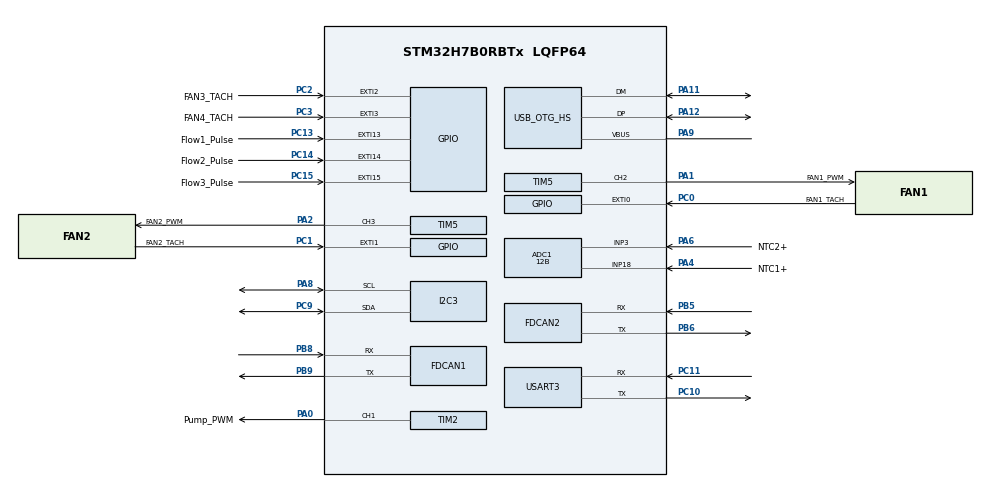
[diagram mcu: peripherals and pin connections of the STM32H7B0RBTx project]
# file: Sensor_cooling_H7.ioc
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ADC1.Channel-0\#ChannelRegularConversion=ADC_CHANNEL_3
ADC1.Channel-1\#ChannelRegularConversion=ADC_CHANNEL_18
ADC1.ClockPrescaler=ADC_CLOCK_ASYNC_DIV64
ADC1.ConversionDataManagement=ADC_CONVERSIONDATA_DMA_CIRCULAR
ADC1.ExternalTrigConv=ADC_EXTERNALTRIG_T6_TRGO
ADC1.NbrOfConversion=2
ADC1.NbrOfConversionFlag=1
ADC1.OffsetNumber-0\#ChannelRegularConversion=ADC_OFFSET_NONE
ADC1.OffsetNumber-1\#ChannelRegularConversion=ADC_OFFSET_NONE
ADC1.OffsetSignedSaturation-0\#ChannelRegularConversion=DISABLE
ADC1.OffsetSignedSaturation-1\#ChannelRegularConversion=DISABLE
ADC1.Rank-0\#ChannelRegularConversion=1
ADC1.Rank-1\#ChannelRegularConversion=2
ADC1.Resolution=ADC_RESOLUTION_12B
ADC1.SamplingTime-0\#ChannelRegularConversion=ADC_SAMPLETIME_810CYCLES_5
ADC1.SamplingTime-1\#ChannelRegularConversion=ADC_SAMPLETIME_810CYCLES_5
ADC1.master=1
Dma.ADC1.0.Direction=DMA_PERIPH_TO_MEMORY
Dma.ADC1.0.EventEnable=DISABLE
Dma.ADC1.0.FIFOMode=DMA_FIFOMODE_DISABLE
Dma.ADC1.0.Instance=DMA1_Stream0
Dma.ADC1.0.MemDataAlignment=DMA_MDATAALIGN_HALFWORD
Dma.ADC1.0.MemInc=DMA_MINC_ENABLE
Dma.ADC1.0.Mode=DMA_CIRCULAR
Dma.ADC1.0.PeriphDataAlignment=DMA_PDATAALIGN_HALFWORD
Dma.ADC1.0.PeriphInc=DMA_PINC_DISABLE
Dma.ADC1.0.Polarity=HAL_DMAMUX_REQ_GEN_RISING
Dma.ADC1.0.Priority=DMA_PRIORITY_LOW
Dma.ADC1.0.RequestNumber=1
Dma.ADC1.0.SignalID=NONE
Dma.ADC1.0.SyncEnable=DISABLE
Dma.ADC1.0.SyncPolarity=HAL_DMAMUX_SYNC_NO_EVENT
Dma.ADC1.0.SyncRequestNumber=1
Dma.ADC1.0.SyncSignalID=NONE
Dma.Request0=ADC1
FDCAN1.CalculateBaudRateNominal=500000
FDCAN1.CalculateTimeBitNominal=2000
FDCAN1.CalculateTimeQuantumNominal=142.85714285714286
FDCAN1.NominalPrescaler=20
FDCAN1.NominalTimeSeg1=11
FDCAN1.NominalTimeSeg2=2
FDCAN1.RxFifo0ElmtsNbr=32
FDCAN1.StdFiltersNbr=1
FDCAN1.TxFifoQueueElmtsNbr=32
FDCAN2.CalculateBaudRateNominal=2916666
FDCAN2.CalculateTimeBitNominal=342
FDCAN2.CalculateTimeQuantumNominal=114.28571428571429
I2C3.Analog_Filter=I2C_ANALOGFILTER_DISABLE
I2C3.OwnAddress=0x50
I2C3.Timing=0x30808BD0
Mcu.Family=STM32H7
Mcu.Name=STM32H7B0RBTx
Mcu.Package=LQFP64
NVIC.ADC_IRQn=true\:0\:0\:false\:false\:true\:true\:true\:true
NVIC.DMA1_Stream0_IRQn=true\:0\:0\:false\:false\:true\:false\:true\:true
NVIC.FDCAN1_IT0_IRQn=true\:0\:0\:false\:false\:true\:true\:true\:true
NVIC.FDCAN1_IT1_IRQn=true\:0\:0\:false\:false\:true\:true\:true\:true
NVIC.PriorityGroup=NVIC_PRIORITYGROUP_4
PA0.GPIO_Label=Pump_PWM
PA0.Signal=S_TIM2_CH1_ETR
PA1.GPIO_Label=FAN1_PWM
PA1.Signal=S_TIM5_CH2
PA11.Mode=Device_Only_FS
PA11.Signal=USB_OTG_HS_DM
PA12.Mode=Device_Only_FS
PA12.Signal=USB_OTG_HS_DP
PA13.Mode=Trace_Asynchronous_SW
PA13.Signal=DEBUG_JTMS-SWDIO
PA14.Mode=Trace_Asynchronous_SW
PA14.Signal=DEBUG_JTCK-SWCLK
PA2.GPIO_Label=FAN2_PWM
PA2.Signal=S_TIM5_CH3
PA4.GPIO_Label=NTC1+
PA4.Signal=ADCx_INP18
PA6.GPIO_Label=NTC2+
PA6.Signal=ADCx_INP3
PA8.Mode=I2C
PA8.Signal=I2C3_SCL
PA9.Mode=Activate_VBUS_FS
PA9.Signal=USB_OTG_HS_VBUS
PB3.Mode=Trace_Asynchronous_SW
PB3.Signal=DEBUG_JTDO-SWO
PB5.Mode=FDCAN_Activate
PB5.Signal=FDCAN2_RX
PB6.Mode=FDCAN_Activate
PB6.Signal=FDCAN2_TX
PB8.Mode=FDCAN_Activate
PB8.Signal=FDCAN1_RX
PB9.Mode=FDCAN_Activate
PB9.Signal=FDCAN1_TX
PC0.GPIO_Label=FAN1_TACH
PC0.Signal=GPXTI0
PC1.GPIO_Label=FAN2_TACH
PC1.Signal=GPXTI1
PC10.Mode=Asynchronous
PC10.Signal=USART3_TX
PC11.Mode=Asynchronous
PC11.Signal=USART3_RX
PC13.GPIO_Label=Flow1_Pulse
PC13.Signal=GPXTI13
PC14-OSC32_IN.GPIO_Label=Flow2_Pulse
PC14-OSC32_IN.Signal=GPXTI14
PC15-OSC32_OUT.GPIO_Label=Flow3_Pulse
PC15-OSC32_OUT.Signal=GPXTI15
PC2.GPIO_Label=FAN3_TACH
PC2.Signal=GPXTI2
PC3.GPIO_Label=FAN4_TACH
PC3.Signal=GPXTI3
PC9.Mode=I2C
PC9.Signal=I2C3_SDA
ProjectManager.HeapSize=0x200
ProjectManager.StackSize=0x400
ProjectManager.TargetToolchain=STM32CubeIDE
RCC.ADCCLockSelection=RCC_ADCCLKSOURCE_PLL3
RCC.ADCFreq_Value=50000000
RCC.APB1Freq_Value=140000000
RCC.APB2Freq_Value=140000000
RCC.APB3Freq_Value=140000000
RCC.APB4Freq_Value=140000000
RCC.CDPPRE=RCC_APB3_DIV2
RCC.CDPPRE1=RCC_APB1_DIV2
RCC.CDPPRE2=RCC_APB2_DIV2
RCC.CortexFreq_Value=280000000
RCC.DIVM1=20
RCC.DIVN1=175
RCC.DIVN2=70
RCC.DIVN3=100
RCC.DIVP2=1
RCC.DIVQ2=1
RCC.DIVR3=4
RCC.FDCANCLockSelection=RCC_FDCANCLKSOURCE_PLL2
RCC.HCLKFreq_Value=280000000
RCC.HSE_VALUE=24000000
RCC.PLL2FRACN=0
RCC.PLL3FRACN=0
RCC.PLLFRACN=0
RCC.PLLSourceVirtual=RCC_PLLSOURCE_HSI
RCC.SRDPPRE=RCC_APB4_DIV2
RCC.SYSCLKFreq_VALUE=280000000
RCC.SYSCLKSource=RCC_SYSCLKSOURCE_PLLCLK
RCC.USBCLockSelection=RCC_USBCLKSOURCE_HSI48
RCC.USBFreq_Value=48000000
SH.ADCx_INP18.0=ADC1_INP18,IN18-Single-Ended
SH.ADCx_INP3.0=ADC1_INP3,IN3-Single-Ended
SH.S_TIM2_CH1_ETR.0=TIM2_CH1,PWM Generation1 CH1
SH.S_TIM5_CH2.0=TIM5_CH2,PWM Generation2 CH2
SH.S_TIM5_CH3.0=TIM5_CH3,PWM Generation3 CH3
TIM2.AutoReloadPreload=TIM_AUTORELOAD_PRELOAD_ENABLE
TIM2.Channel-PWM\ Generation1\ CH1=TIM_CHANNEL_1
TIM2.OCPolarity_1=TIM_OCPOLARITY_LOW
TIM2.Period=61399
TIM2.Pulse-PWM\ Generation1\ CH1=280000
TIM5.AutoReloadPreload=TIM_AUTORELOAD_PRELOAD_ENABLE
TIM5.Channel-PWM\ Generation2\ CH2=TIM_CHANNEL_2
TIM5.Channel-PWM\ Generation3\ CH3=TIM_CHANNEL_3
TIM5.OCPolarity_2=TIM_OCPOLARITY_LOW
TIM5.OCPolarity_3=TIM_OCPOLARITY_LOW
TIM5.Period=11199
TIM5.Pulse-PWM\ Generation2\ CH2=5600
TIM6.Period=62499
TIM6.Prescaler=2239
TIM6.TIM_MasterOutputTrigger=TIM_TRGO_UPDATE
USART3.VirtualMode-Asynchronous=VM_ASYNC
USB_OTG_HS.VirtualMode=Device_Only_FS
VP_MEMORYMAP_VS_MEMORYMAP.Mode=CurAppReg
VP_TIM6_VS_ClockSourceINT.Mode=Enable_Timer
board=custom

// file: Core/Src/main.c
/* USER CODE BEGIN Header */
/**
  ******************************************************************************
  * @file           : main.c
  * @brief          : Main program body
  ******************************************************************************
  * @attention
  *
  * Copyright (c) 2026 STMicroelectronics.
  * All rights reserved.
  *
  * This software is licensed under terms that can be found in the LICENSE file
  * in the root directory of this software component.
  * If no LICENSE file comes with this software, it is provided AS-IS.
  *
  ******************************************************************************
  */
/* USER CODE END Header */
#include "main.h"

/* USER CODE BEGIN Includes */

#include "MainController.h"

/* USER CODE END Includes */

ADC_HandleTypeDef hadc1;
DMA_HandleTypeDef hdma_adc1;

FDCAN_HandleTypeDef hfdcan1;
FDCAN_HandleTypeDef hfdcan2;

I2C_HandleTypeDef hi2c3;

TIM_HandleTypeDef htim2;
TIM_HandleTypeDef htim5;
TIM_HandleTypeDef htim6;

UART_HandleTypeDef huart3;

PCD_HandleTypeDef hpcd_USB_OTG_HS;

void SystemClock_Config(void);
void PeriphCommonClock_Config(void);
static void MX_GPIO_Init(void);
static void MX_DMA_Init(void);
static void MX_ADC1_Init(void);
static void MX_FDCAN1_Init(void);
static void MX_FDCAN2_Init(void);
static void MX_I2C3_Init(void);
static void MX_TIM5_Init(void);
static void MX_USART3_UART_Init(void);
static void MX_USB_OTG_HS_PCD_Init(void);
static void MX_TIM2_Init(void);
static void MX_TIM6_Init(void);

int main(void)
{

  /* MCU Configuration--------------------------------------------------------*/

  /* Reset of all peripherals, Initializes the Flash interface and the Systick. */
  HAL_Init();

  /* Configure the system clock */
  SystemClock_Config();

  /* Configure the peripherals common clocks */
  PeriphCommonClock_Config();

  /* Initialize all configured peripherals */
  MX_GPIO_Init();
  MX_DMA_Init();
  MX_ADC1_Init();
  MX_FDCAN1_Init();
  MX_FDCAN2_Init();
  MX_I2C3_Init();
  MX_TIM5_Init();
  MX_USART3_UART_Init();
  MX_USB_OTG_HS_PCD_Init();
  MX_TIM2_Init();
  MX_TIM6_Init();
  /* USER CODE BEGIN 2 */

  MainController_Init();

  /* USER CODE END 2 */

  /* Infinite loop */
  while (1)
  {

    /* USER CODE BEGIN 3 */
	MainController_Run();
  }
  /* USER CODE END 3 */
}

void SystemClock_Config(void)
{
  RCC_OscInitTypeDef RCC_OscInitStruct = {0};
  RCC_ClkInitTypeDef RCC_ClkInitStruct = {0};

  /*AXI clock gating */
  RCC->CKGAENR = 0xE003FFFF;

  /** Supply configuration update enable
  */
  HAL_PWREx_ConfigSupply(PWR_LDO_SUPPLY);

  /** Configure the main internal regulator output voltage
  */
  __HAL_PWR_VOLTAGESCALING_CONFIG(PWR_REGULATOR_VOLTAGE_SCALE0);

  while(!__HAL_PWR_GET_FLAG(PWR_FLAG_VOSRDY)) {}

  /** Initializes the RCC Oscillators according to the specified parameters
  * in the RCC_OscInitTypeDef structure.
  */
  RCC_OscInitStruct.OscillatorType = RCC_OSCILLATORTYPE_HSI48|RCC_OSCILLATORTYPE_HSI;
  RCC_OscInitStruct.HSIState = RCC_HSI_DIV1;
  RCC_OscInitStruct.HSICalibrationValue = 64;
  RCC_OscInitStruct.HSI48State = RCC_HSI48_ON;
  RCC_OscInitStruct.PLL.PLLState = RCC_PLL_ON;
  RCC_OscInitStruct.PLL.PLLSource = RCC_PLLSOURCE_HSI;
  RCC_OscInitStruct.PLL.PLLM = 20;
  RCC_OscInitStruct.PLL.PLLN = 175;
  RCC_OscInitStruct.PLL.PLLP = 2;
  RCC_OscInitStruct.PLL.PLLQ = 2;
  RCC_OscInitStruct.PLL.PLLR = 2;
  RCC_OscInitStruct.PLL.PLLRGE = RCC_PLL1VCIRANGE_1;
  RCC_OscInitStruct.PLL.PLLVCOSEL = RCC_PLL1VCOWIDE;
  RCC_OscInitStruct.PLL.PLLFRACN = 0;
  if (HAL_RCC_OscConfig(&RCC_OscInitStruct) != HAL_OK)
  {
    Error_Handler();
  }

  /** Initializes the CPU, AHB and APB buses clocks
  */
  RCC_ClkInitStruct.ClockType = RCC_CLOCKTYPE_HCLK|RCC_CLOCKTYPE_SYSCLK
                              |RCC_CLOCKTYPE_PCLK1|RCC_CLOCKTYPE_PCLK2
                              |RCC_CLOCKTYPE_D3PCLK1|RCC_CLOCKTYPE_D1PCLK1;
  RCC_ClkInitStruct.SYSCLKSource = RCC_SYSCLKSOURCE_PLLCLK;
  RCC_ClkInitStruct.SYSCLKDivider = RCC_SYSCLK_DIV1;
  RCC_ClkInitStruct.AHBCLKDivider = RCC_HCLK_DIV1;
  RCC_ClkInitStruct.APB3CLKDivider = RCC_APB3_DIV2;
  RCC_ClkInitStruct.APB1CLKDivider = RCC_APB1_DIV2;
  RCC_ClkInitStruct.APB2CLKDivider = RCC_APB2_DIV2;
  RCC_ClkInitStruct.APB4CLKDivider = RCC_APB4_DIV2;

  if (HAL_RCC_ClockConfig(&RCC_ClkInitStruct, FLASH_LATENCY_6) != HAL_OK)
  {
    Error_Handler();
  }
}

void PeriphCommonClock_Config(void)
{
  RCC_PeriphCLKInitTypeDef PeriphClkInitStruct = {0};

  /** Initializes the peripherals clock
  */
  PeriphClkInitStruct.PeriphClockSelection = RCC_PERIPHCLK_FDCAN;
  PeriphClkInitStruct.PLL2.PLL2M = 32;
  PeriphClkInitStruct.PLL2.PLL2N = 70;
  PeriphClkInitStruct.PLL2.PLL2P = 1;
  PeriphClkInitStruct.PLL2.PLL2Q = 1;
  PeriphClkInitStruct.PLL2.PLL2R = 2;
  PeriphClkInitStruct.PLL2.PLL2RGE = RCC_PLL2VCIRANGE_1;
  PeriphClkInitStruct.PLL2.PLL2VCOSEL = RCC_PLL2VCOWIDE;
  PeriphClkInitStruct.PLL2.PLL2FRACN = 0;
  PeriphClkInitStruct.FdcanClockSelection = RCC_FDCANCLKSOURCE_PLL2;
  if (HAL_RCCEx_PeriphCLKConfig(&PeriphClkInitStruct) != HAL_OK)
  {
    Error_Handler();
  }
}

static void MX_ADC1_Init(void)
{

  ADC_MultiModeTypeDef multimode = {0};
  ADC_ChannelConfTypeDef sConfig = {0};

  /** Common config
  */
  hadc1.Instance = ADC1;
  hadc1.Init.ClockPrescaler = ADC_CLOCK_ASYNC_DIV64;
  hadc1.Init.Resolution = ADC_RESOLUTION_12B;
  hadc1.Init.ScanConvMode = ADC_SCAN_ENABLE;
  hadc1.Init.EOCSelection = ADC_EOC_SINGLE_CONV;
  hadc1.Init.LowPowerAutoWait = DISABLE;
  hadc1.Init.ContinuousConvMode = DISABLE;
  hadc1.Init.NbrOfConversion = 2;
  hadc1.Init.DiscontinuousConvMode = DISABLE;
  hadc1.Init.ExternalTrigConv = ADC_EXTERNALTRIG_T6_TRGO;
  hadc1.Init.ExternalTrigConvEdge = ADC_EXTERNALTRIGCONVEDGE_RISING;
  hadc1.Init.ConversionDataManagement = ADC_CONVERSIONDATA_DMA_CIRCULAR;
  hadc1.Init.Overrun = ADC_OVR_DATA_PRESERVED;
  hadc1.Init.LeftBitShift = ADC_LEFTBITSHIFT_NONE;
  hadc1.Init.OversamplingMode = DISABLE;
  if (HAL_ADC_Init(&hadc1) != HAL_OK)
  {
    Error_Handler();
  }

  /** Configure the ADC multi-mode
  */
  multimode.Mode = ADC_MODE_INDEPENDENT;
  if (HAL_ADCEx_MultiModeConfigChannel(&hadc1, &multimode) != HAL_OK)
  {
    Error_Handler();
  }

  /** Configure Regular Channel
  */
  sConfig.Channel = ADC_CHANNEL_3;
  sConfig.Rank = ADC_REGULAR_RANK_1;
  sConfig.SamplingTime = ADC_SAMPLETIME_810CYCLES_5;
  sConfig.SingleDiff = ADC_SINGLE_ENDED;
  sConfig.OffsetNumber = ADC_OFFSET_NONE;
  sConfig.Offset = 0;
  sConfig.OffsetSignedSaturation = DISABLE;
  if (HAL_ADC_ConfigChannel(&hadc1, &sConfig) != HAL_OK)
  {
    Error_Handler();
  }

  /** Configure Regular Channel
  */
  sConfig.Channel = ADC_CHANNEL_18;
  sConfig.Rank = ADC_REGULAR_RANK_2;
  if (HAL_ADC_ConfigChannel(&hadc1, &sConfig) != HAL_OK)
  {
    Error_Handler();
  }

}

static void MX_FDCAN1_Init(void)
{

  hfdcan1.Instance = FDCAN1;
  hfdcan1.Init.FrameFormat = FDCAN_FRAME_CLASSIC;
  hfdcan1.Init.Mode = FDCAN_MODE_NORMAL;
  hfdcan1.Init.AutoRetransmission = DISABLE;
  hfdcan1.Init.TransmitPause = DISABLE;
  hfdcan1.Init.ProtocolException = DISABLE;
  hfdcan1.Init.NominalPrescaler = 20;
  hfdcan1.Init.NominalSyncJumpWidth = 1;
  hfdcan1.Init.NominalTimeSeg1 = 11;
  hfdcan1.Init.NominalTimeSeg2 = 2;
  hfdcan1.Init.DataPrescaler = 1;
  hfdcan1.Init.DataSyncJumpWidth = 1;
  hfdcan1.Init.DataTimeSeg1 = 1;
  hfdcan1.Init.DataTimeSeg2 = 1;
  hfdcan1.Init.MessageRAMOffset = 0;
  hfdcan1.Init.StdFiltersNbr = 1;
  hfdcan1.Init.ExtFiltersNbr = 0;
  hfdcan1.Init.RxFifo0ElmtsNbr = 32;
  hfdcan1.Init.RxFifo0ElmtSize = FDCAN_DATA_BYTES_8;
  hfdcan1.Init.RxFifo1ElmtsNbr = 0;
  hfdcan1.Init.RxFifo1ElmtSize = FDCAN_DATA_BYTES_8;
  hfdcan1.Init.RxBuffersNbr = 0;
  hfdcan1.Init.RxBufferSize = FDCAN_DATA_BYTES_8;
  hfdcan1.Init.TxEventsNbr = 0;
  hfdcan1.Init.TxBuffersNbr = 0;
  hfdcan1.Init.TxFifoQueueElmtsNbr = 32;
  hfdcan1.Init.TxFifoQueueMode = FDCAN_TX_FIFO_OPERATION;
  hfdcan1.Init.TxElmtSize = FDCAN_DATA_BYTES_8;
  if (HAL_FDCAN_Init(&hfdcan1) != HAL_OK)
  {
    Error_Handler();
  }

}

static void MX_FDCAN2_Init(void)
{

  hfdcan2.Instance = FDCAN2;
  hfdcan2.Init.FrameFormat = FDCAN_FRAME_CLASSIC;
  hfdcan2.Init.Mode = FDCAN_MODE_NORMAL;
  hfdcan2.Init.AutoRetransmission = DISABLE;
  hfdcan2.Init.TransmitPause = DISABLE;
  hfdcan2.Init.ProtocolException = DISABLE;
  hfdcan2.Init.NominalPrescaler = 16;
  hfdcan2.Init.NominalSyncJumpWidth = 1;
  hfdcan2.Init.NominalTimeSeg1 = 1;
  hfdcan2.Init.NominalTimeSeg2 = 1;
  hfdcan2.Init.DataPrescaler = 1;
  hfdcan2.Init.DataSyncJumpWidth = 1;
  hfdcan2.Init.DataTimeSeg1 = 1;
  hfdcan2.Init.DataTimeSeg2 = 1;
  hfdcan2.Init.MessageRAMOffset = 0;
  hfdcan2.Init.StdFiltersNbr = 0;
  hfdcan2.Init.ExtFiltersNbr = 0;
  hfdcan2.Init.RxFifo0ElmtsNbr = 0;
  hfdcan2.Init.RxFifo0ElmtSize = FDCAN_DATA_BYTES_8;
  hfdcan2.Init.RxFifo1ElmtsNbr = 0;
  hfdcan2.Init.RxFifo1ElmtSize = FDCAN_DATA_BYTES_8;
  hfdcan2.Init.RxBuffersNbr = 0;
  hfdcan2.Init.RxBufferSize = FDCAN_DATA_BYTES_8;
  hfdcan2.Init.TxEventsNbr = 0;
  hfdcan2.Init.TxBuffersNbr = 0;
  hfdcan2.Init.TxFifoQueueElmtsNbr = 0;
  hfdcan2.Init.TxFifoQueueMode = FDCAN_TX_FIFO_OPERATION;
  hfdcan2.Init.TxElmtSize = FDCAN_DATA_BYTES_8;
  if (HAL_FDCAN_Init(&hfdcan2) != HAL_OK)
  {
    Error_Handler();
  }

}

static void MX_I2C3_Init(void)
{

  hi2c3.Instance = I2C3;
  hi2c3.Init.Timing = 0x30808BD0;
  hi2c3.Init.OwnAddress1 = 160;
  hi2c3.Init.AddressingMode = I2C_ADDRESSINGMODE_7BIT;
  hi2c3.Init.DualAddressMode = I2C_DUALADDRESS_DISABLE;
  hi2c3.Init.OwnAddress2 = 0;
  hi2c3.Init.OwnAddress2Masks = I2C_OA2_NOMASK;
  hi2c3.Init.GeneralCallMode = I2C_GENERALCALL_DISABLE;
  hi2c3.Init.NoStretchMode = I2C_NOSTRETCH_DISABLE;
  if (HAL_I2C_Init(&hi2c3) != HAL_OK)
  {
    Error_Handler();
  }

  /** Configure Analogue filter
  */
  if (HAL_I2CEx_ConfigAnalogFilter(&hi2c3, I2C_ANALOGFILTER_DISABLE) != HAL_OK)
  {
    Error_Handler();
  }

  /** Configure Digital filter
  */
  if (HAL_I2CEx_ConfigDigitalFilter(&hi2c3, 0) != HAL_OK)
  {
    Error_Handler();
  }

}

static void MX_TIM2_Init(void)
{

  TIM_MasterConfigTypeDef sMasterConfig = {0};
  TIM_OC_InitTypeDef sConfigOC = {0};

  htim2.Instance = TIM2;
  htim2.Init.Prescaler = 0;
  htim2.Init.CounterMode = TIM_COUNTERMODE_UP;
  htim2.Init.Period = 61399;
  htim2.Init.ClockDivision = TIM_CLOCKDIVISION_DIV1;
  htim2.Init.AutoReloadPreload = TIM_AUTORELOAD_PRELOAD_ENABLE;
  if (HAL_TIM_PWM_Init(&htim2) != HAL_OK)
  {
    Error_Handler();
  }
  sMasterConfig.MasterOutputTrigger = TIM_TRGO_RESET;
  sMasterConfig.MasterSlaveMode = TIM_MASTERSLAVEMODE_DISABLE;
  if (HAL_TIMEx_MasterConfigSynchronization(&htim2, &sMasterConfig) != HAL_OK)
  {
    Error_Handler();
  }
  sConfigOC.OCMode = TIM_OCMODE_PWM1;
  sConfigOC.Pulse = 280000;
  sConfigOC.OCPolarity = TIM_OCPOLARITY_LOW;
  sConfigOC.OCFastMode = TIM_OCFAST_DISABLE;
  if (HAL_TIM_PWM_ConfigChannel(&htim2, &sConfigOC, TIM_CHANNEL_1) != HAL_OK)
  {
    Error_Handler();
  }
  HAL_TIM_MspPostInit(&htim2);

}

static void MX_TIM5_Init(void)
{

  TIM_MasterConfigTypeDef sMasterConfig = {0};
  TIM_OC_InitTypeDef sConfigOC = {0};

  htim5.Instance = TIM5;
  htim5.Init.Prescaler = 0;
  htim5.Init.CounterMode = TIM_COUNTERMODE_UP;
  htim5.Init.Period = 11199;
  htim5.Init.ClockDivision = TIM_CLOCKDIVISION_DIV1;
  htim5.Init.AutoReloadPreload = TIM_AUTORELOAD_PRELOAD_ENABLE;
  if (HAL_TIM_PWM_Init(&htim5) != HAL_OK)
  {
    Error_Handler();
  }
  sMasterConfig.MasterOutputTrigger = TIM_TRGO_RESET;
  sMasterConfig.MasterSlaveMode = TIM_MASTERSLAVEMODE_DISABLE;
  if (HAL_TIMEx_MasterConfigSynchronization(&htim5, &sMasterConfig) != HAL_OK)
  {
    Error_Handler();
  }
  sConfigOC.OCMode = TIM_OCMODE_PWM1;
  sConfigOC.Pulse = 5600;
  sConfigOC.OCPolarity = TIM_OCPOLARITY_LOW;
  sConfigOC.OCFastMode = TIM_OCFAST_DISABLE;
  if (HAL_TIM_PWM_ConfigChannel(&htim5, &sConfigOC, TIM_CHANNEL_2) != HAL_OK)
  {
    Error_Handler();
  }
  sConfigOC.Pulse = 0;
  if (HAL_TIM_PWM_ConfigChannel(&htim5, &sConfigOC, TIM_CHANNEL_3) != HAL_OK)
  {
    Error_Handler();
  }
  HAL_TIM_MspPostInit(&htim5);

}

static void MX_TIM6_Init(void)
{

  TIM_MasterConfigTypeDef sMasterConfig = {0};

  htim6.Instance = TIM6;
  htim6.Init.Prescaler = 2239;
  htim6.Init.CounterMode = TIM_COUNTERMODE_UP;
  htim6.Init.Period = 62499;
  htim6.Init.AutoReloadPreload = TIM_AUTORELOAD_PRELOAD_DISABLE;
  if (HAL_TIM_Base_Init(&htim6) != HAL_OK)
  {
    Error_Handler();
  }
  sMasterConfig.MasterOutputTrigger = TIM_TRGO_UPDATE;
  sMasterConfig.MasterSlaveMode = TIM_MASTERSLAVEMODE_DISABLE;
  if (HAL_TIMEx_MasterConfigSynchronization(&htim6, &sMasterConfig) != HAL_OK)
  {
    Error_Handler();
  }

}

static void MX_USART3_UART_Init(void)
{

  huart3.Instance = USART3;
  huart3.Init.BaudRate = 115200;
  huart3.Init.WordLength = UART_WORDLENGTH_8B;
  huart3.Init.StopBits = UART_STOPBITS_1;
  huart3.Init.Parity = UART_PARITY_NONE;
  huart3.Init.Mode = UART_MODE_TX_RX;
  huart3.Init.HwFlowCtl = UART_HWCONTROL_NONE;
  huart3.Init.OverSampling = UART_OVERSAMPLING_16;
  huart3.Init.OneBitSampling = UART_ONE_BIT_SAMPLE_DISABLE;
  huart3.Init.ClockPrescaler = UART_PRESCALER_DIV1;
  huart3.AdvancedInit.AdvFeatureInit = UART_ADVFEATURE_NO_INIT;
  if (HAL_UART_Init(&huart3) != HAL_OK)
  {
    Error_Handler();
  }
  if (HAL_UARTEx_SetTxFifoThreshold(&huart3, UART_TXFIFO_THRESHOLD_1_8) != HAL_OK)
  {
    Error_Handler();
  }
  if (HAL_UARTEx_SetRxFifoThreshold(&huart3, UART_RXFIFO_THRESHOLD_1_8) != HAL_OK)
  {
    Error_Handler();
  }
  if (HAL_UARTEx_DisableFifoMode(&huart3) != HAL_OK)
  {
    Error_Handler();
  }

}

static void MX_USB_OTG_HS_PCD_Init(void)
{

  hpcd_USB_OTG_HS.Instance = USB_OTG_HS;
  hpcd_USB_OTG_HS.Init.dev_endpoints = 9;
  hpcd_USB_OTG_HS.Init.speed = PCD_SPEED_FULL;
  hpcd_USB_OTG_HS.Init.dma_enable = DISABLE;
  hpcd_USB_OTG_HS.Init.phy_itface = USB_OTG_EMBEDDED_PHY;
  hpcd_USB_OTG_HS.Init.Sof_enable = DISABLE;
  hpcd_USB_OTG_HS.Init.low_power_enable = DISABLE;
  hpcd_USB_OTG_HS.Init.lpm_enable = DISABLE;
  hpcd_USB_OTG_HS.Init.vbus_sensing_enable = ENABLE;
  hpcd_USB_OTG_HS.Init.use_dedicated_ep1 = DISABLE;
  hpcd_USB_OTG_HS.Init.use_external_vbus = DISABLE;
  if (HAL_PCD_Init(&hpcd_USB_OTG_HS) != HAL_OK)
  {
    Error_Handler();
  }

}

static void MX_DMA_Init(void)
{

  /* DMA controller clock enable */
  __HAL_RCC_DMA1_CLK_ENABLE();

  /* DMA interrupt init */
  /* DMA1_Stream0_IRQn interrupt configuration */
  HAL_NVIC_SetPriority(DMA1_Stream0_IRQn, 0, 0);
  HAL_NVIC_EnableIRQ(DMA1_Stream0_IRQn);

}

static void MX_GPIO_Init(void)
{
  GPIO_InitTypeDef GPIO_InitStruct = {0};

  /* GPIO Ports Clock Enable */
  __HAL_RCC_GPIOC_CLK_ENABLE();
  __HAL_RCC_GPIOA_CLK_ENABLE();
  __HAL_RCC_GPIOB_CLK_ENABLE();

  /*Configure GPIO pins : Flow1_Pulse_Pin Flow2_Pulse_Pin Flow3_Pulse_Pin FAN1_TACH_Pin
                           FAN2_TACH_Pin FAN3_TACH_Pin FAN4_TACH_Pin */
  GPIO_InitStruct.Pin = Flow1_Pulse_Pin|Flow2_Pulse_Pin|Flow3_Pulse_Pin|FAN1_TACH_Pin
                          |FAN2_TACH_Pin|FAN3_TACH_Pin|FAN4_TACH_Pin;
  GPIO_InitStruct.Mode = GPIO_MODE_IT_RISING;
  GPIO_InitStruct.Pull = GPIO_NOPULL;
  HAL_GPIO_Init(GPIOC, &GPIO_InitStruct);

}

void Error_Handler(void)
{
  __disable_irq();
  while (1)
  {
  }
}
